# ATxmega128A1U device description
Architecture: AVR8_XMEGA; Family: AVR XMEGA
Registers are 8-bit, access not given, no defined reset value unless marked. A register's access mark holds for its fields unless they carry their own. Offsets are from the block's base; [hi:lo] are bit positions; lines under a group give offsets from that group; 'fields as' and 'values as' point back to an identical list.

## TWI — Two-Wire Interface
Instances: TWIC 0x480, TWID 0x490, TWIE 0x4A0, TWIF 0x4B0
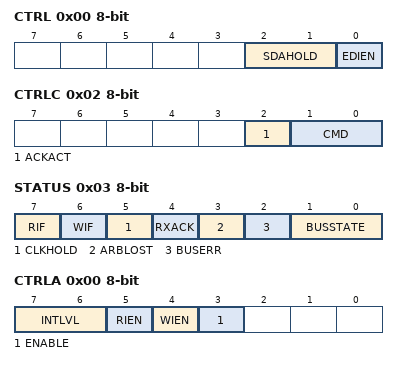
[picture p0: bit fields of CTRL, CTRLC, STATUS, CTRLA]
0x00 CTRL — TWI Common Control Register
  [2:1] SDAHOLD — SDA Hold Time Enable
    0=OFF (SDA hold time off); 1=50NS (Typical 50ns hold time); 2=300NS (Typical 300ns hold time); 3=400NS (Typical 400ns hold time)
  [0] EDIEN — External Driver Interface Enable
0x01 MASTER group — TWI master module
  0x00 CTRLA — Control Register A
    [7:6] INTLVL — Interrupt Level
      0=OFF (Interrupt Disabled); 1=LO (Low Level); 2=MED (Medium Level); 3=HI (High Level)
    [5] RIEN — Read Interrupt Enable
    [4] WIEN — Write Interrupt Enable
    [3] ENABLE — Enable TWI Master
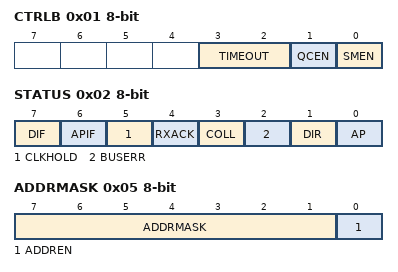
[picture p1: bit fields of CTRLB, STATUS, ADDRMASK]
  0x01 CTRLB — Control Register B
    [3:2] TIMEOUT — Inactive Bus timeout
      0=DISABLED (Bus Timeout Disabled); 1=50US (50 Microseconds); 2=100US (100 Microseconds); 3=200US (200 Microseconds)
    [1] QCEN — Quick Command Enable
    [0] SMEN — Smart Mode Enable
  0x02 CTRLC — Control Register C
    [2] ACKACT — Acknowledge Action
    [1:0] CMD — Command
      0=NOACT (No Action); 1=REPSTART (Issue Repeated Start Condition); 2=RECVTRANS (Receive or Transmit Data); 3=STOP (Issue Stop Condition)
  0x03 STATUS
    [7] RIF — Read Interrupt Flag
    [6] WIF — Write Interrupt Flag
    [5] CLKHOLD — Clock Hold
    [4] RXACK — Received Acknowledge
    [3] ARBLOST — Arbitration Lost
    [2] BUSERR — Bus Error
    [1:0] BUSSTATE
      0=UNKNOWN (Unknown Bus State); 1=IDLE (Bus is Idle); 2=OWNER (This Module Controls The Bus); 3=BUSY (The Bus is Busy)
  0x04 BAUD — Baurd Rate Control Register
  0x05 ADDR — Address Register
  0x06 DATA
0x08 SLAVE group — TWI slave module
  0x00 CTRLA — Control Register A
    [7:6] INTLVL — Interrupt Level
      values as MASTER.CTRLA.INTLVL
    [5] DIEN — Data Interrupt Enable
    [4] APIEN — Address/Stop Interrupt Enable
    [3] ENABLE — Enable TWI Slave
    [2] PIEN — Stop Interrupt Enable
    [1] PMEN — Promiscuous Mode Enable
    [0] SMEN — Smart Mode Enable
  0x01 CTRLB — Control Register B
    [2] ACKACT — Acknowledge Action
    [1:0] CMD — Command
      0=NOACT (No Action); 2=COMPTRANS (Used To Complete a Transaction); 3=RESPONSE (Used in Response to Address/Data Interrupt)
  0x02 STATUS
    [7] DIF — Data Interrupt Flag
    [6] APIF — Address/Stop Interrupt Flag
    [5] CLKHOLD — Clock Hold
    [4] RXACK — Received Acknowledge
    [3] COLL — Collision
    [2] BUSERR — Bus Error
    [1] DIR — Read/Write Direction
    [0] AP — Slave Address or Stop
  0x03 ADDR — Address Register
  0x04 DATA
  0x05 ADDRMASK — Address Mask Register
    [7:1] ADDRMASK — Address Mask
    [0] ADDREN — Address Enable

## USB — Universal Serial Bus
Instances: USB 0x4C0
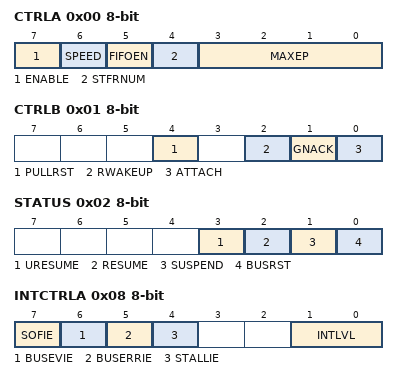
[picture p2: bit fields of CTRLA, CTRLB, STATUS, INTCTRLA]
0x00 CTRLA — Control Register A
  [7] ENABLE — USB Enable
  [6] SPEED — Speed Select
  [5] FIFOEN — USB FIFO Enable
  [4] STFRNUM — Store Frame Number Enable
  [3:0] MAXEP — Maximum Endpoint Addresses
0x01 CTRLB — Control Register B
  [4] PULLRST — Pull during Reset
  [2] RWAKEUP — Remote Wake-up
  [1] GNACK — Global NACK
  [0] ATTACH
0x02 STATUS
  [3] URESUME — Upstream Resume
  [2] RESUME
  [1] SUSPEND — Bus Suspended
  [0] BUSRST — Bus Reset
0x03 ADDR — Address Register
  [6:0] ADDR — Device Address
0x04 FIFOWP — FIFO Write Pointer Register
  [4:0] FIFOWP — FIFO Write Pointer
0x05 FIFORP — FIFO Read Pointer Register
  [4:0] FIFORP — FIFO Read Pointer
0x06 EPPTR 16-bit — Endpoint Configuration Table Pointer
0x08 INTCTRLA — Interrupt Control Register A
  [7] SOFIE — Start Of Frame Interrupt Enable
  [6] BUSEVIE — Bus Event Interrupt Enable
  [5] BUSERRIE — Bus Error Interrupt Enable
  [4] STALLIE — STALL Interrupt Enable
  [1:0] INTLVL — Interrupt Level
    0=OFF (Interrupt disabled); 1=LO (Low level); 2=MED (Medium level); 3=HI (High level)
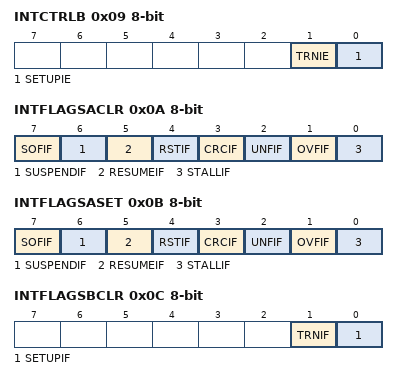
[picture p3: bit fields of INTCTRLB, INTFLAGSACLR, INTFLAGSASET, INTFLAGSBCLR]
0x09 INTCTRLB — Interrupt Control Register B
  [1] TRNIE — Transaction Complete Interrupt Enable
  [0] SETUPIE — SETUP Transaction Complete Interrupt Enable
0x0A INTFLAGSACLR — Clear Interrupt Flag Register A
  [7] SOFIF — Start Of Frame Interrupt Flag
  [6] SUSPENDIF — Suspend Interrupt Flag
  [5] RESUMEIF — Resume Interrupt Flag
  [4] RSTIF — Reset Interrupt Flag
  [3] CRCIF — Isochronous CRC Error Interrupt Flag
  [2] UNFIF — Underflow Interrupt Flag
  [1] OVFIF — Overflow Interrupt Flag
  [0] STALLIF — STALL Interrupt Flag
0x0B INTFLAGSASET — Set Interrupt Flag Register A
  fields as INTFLAGSACLR
0x0C INTFLAGSBCLR — Clear Interrupt Flag Register B
  [1] TRNIF — Transaction Complete Interrupt Flag
  [0] SETUPIF — SETUP Transaction Complete Interrupt Flag
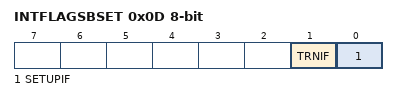
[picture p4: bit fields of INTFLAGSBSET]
0x0D INTFLAGSBSET — Set Interrupt Flag Register B
  fields as INTFLAGSBCLR
0x3A CAL0 — Calibration Byte 0
0x3B CAL1 — Calibration Byte 1
